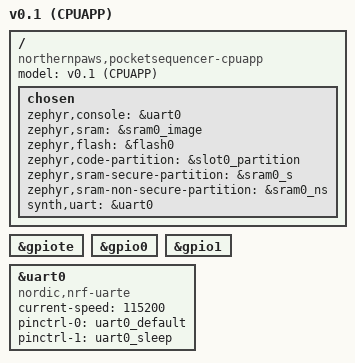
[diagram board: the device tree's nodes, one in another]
/dts-v1/;
#include <nordic/nrf5340_cpuapp_qkaa.dtsi>
#include "pocketsequencer-pinctrl.dtsi"

/ {
	model = "v0.1 (CPUAPP)";
	compatible = "northernpaws,pocketsequencer-cpuapp";

	chosen {
		zephyr,console = &uart0;
		zephyr,sram = &sram0_image;
		zephyr,flash = &flash0;
		zephyr,code-partition = &slot0_partition;
		zephyr,sram-secure-partition = &sram0_s;
		zephyr,sram-non-secure-partition = &sram0_ns;

		synth,uart = &uart0;
	};
};

&gpiote {
    status = "okay";
};

&gpio0 {
	status = "okay";
};

&gpio1 {
	status = "okay";
};

&uart0 {
	status = "okay";
	compatible = "nordic,nrf-uarte";
	current-speed = <115200>;
	pinctrl-0 = <&uart0_default>;
	pinctrl-1 = <&uart0_sleep>;
	pinctrl-names = "default", "sleep";
};

#include "pocketsequencer-cpuapp_partitioning.dtsi"
#include "pocketsequencer-shared_sram.dtsi"
